VERSION ""

NS_ :

BS_:

BU_: XXX

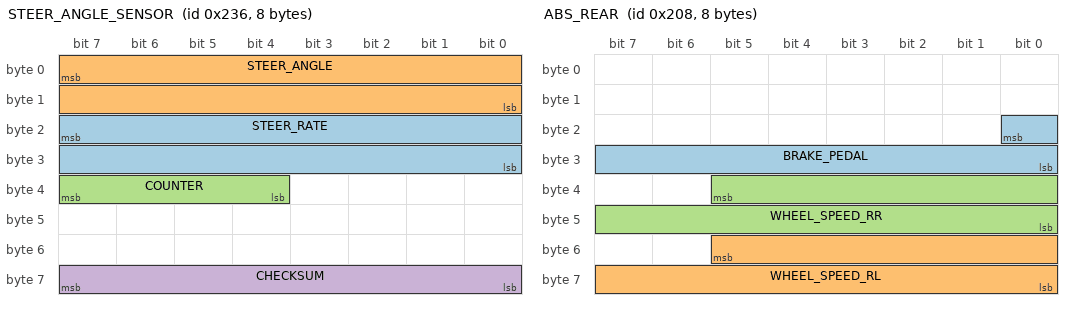
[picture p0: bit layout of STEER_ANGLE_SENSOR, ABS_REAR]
BO_ 566 STEER_ANGLE_SENSOR: 8 XXX
 SG_ STEER_RATE : 23|16@0- (0.5,-2048) [0|65535] "" XXX
 SG_ STEER_ANGLE : 7|16@0- (0.5,-2048) [0|65535] "deg" XXX
 SG_ COUNTER : 39|4@0+ (1,0) [0|15] "" XXX
 SG_ CHECKSUM : 63|8@0+ (1,0) [0|255] "" XXX

BO_ 664 MOTOR: 8 XXX
 SG_ TEMPERATURE : 8|8@1+ (1,-40) [0|255] "" XXX
 SG_ RPM : 55|16@0- (0.018181818,-181.81818181) [0|65535] "" XXX

BO_ 754 STEER_TORQUE: 3 XXX
 SG_ TORQUE_SENSOR : 7|8@0+ (1,0) [0|65535] "nm" XXX

BO_ 528 GAS: 7 XXX
 SG_ GAS_PEDAL : 23|8@0+ (1,0) [0|65535] "" XXX

BO_ 520 ABS_REAR: 8 XXX
 SG_ BRAKE_PEDAL : 16|9@0+ (1,0) [0|255] "" XXX
 SG_ WHEEL_SPEED_RL : 53|14@0+ (1,0) [0|65535] "" XXX
 SG_ WHEEL_SPEED_RR : 37|14@0+ (1,0) [0|65535] "" XXX

BO_ 512 ABS_FRONT: 8 XXX
 SG_ WHEEL_SPEED_FL : 21|14@0+ (1,0) [0|16383] "" XXX
 SG_ WHEEL_SPEED_FR : 37|14@0+ (1,0) [0|16383] "" XXX

BO_ 561 BRAKE_PRESSED: 8 XXX
 SG_ BRAKE_PRESSED : 33|1@0+ (1,0) [0|1] "" XXX

BO_ 1042 COMBOMETER: 8 XXX
 SG_ SPEED : 15|8@0+ (1,0) [0|65535] "km/h" XXX
 SG_ ODOMETER : 23|24@0+ (1,0) [0|16777215] "" XXX

BO_ 1048 GEAR_PACKET: 7 XXX
 SG_ GEAR : 7|8@0+ (1,0) [0|255] "ascii" XXX

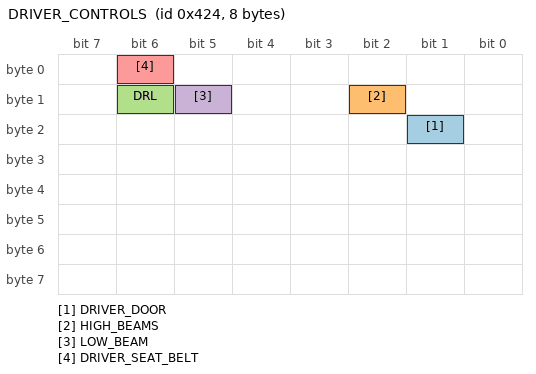
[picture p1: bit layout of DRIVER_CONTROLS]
BO_ 1060 DRIVER_CONTROLS: 8 XXX
 SG_ DRIVER_DOOR : 17|1@0+ (1,0) [0|1] "" XXX
 SG_ HIGH_BEAMS : 10|1@0+ (1,0) [0|1] "" XXX
 SG_ DRL : 14|1@0+ (1,0) [0|1] "" XXX
 SG_ LOW_BEAM : 13|1@0+ (1,0) [0|1] "" XXX
 SG_ DRIVER_SEAT_BELT : 6|1@0+ (1,0) [0|1] "" XXX

BO_ 883 POWER_DATA: 8 XXX
 SG_ BATTERY_CURRENT : 23|16@0+ (0.01,-327.68) [0|65535] "" XXX
 SG_ BATTERY_VOLTAGE : 39|16@0+ (0.1,0) [0|65535] "" XXX

BO_ 838 RANGE: 8 XXX
 SG_ RANGE : 63|8@0+ (1,0) [0|255] "" XXX

CM_ SG_ 1060 DRIVER_SEAT_BELT "1 is off 0 is on";
